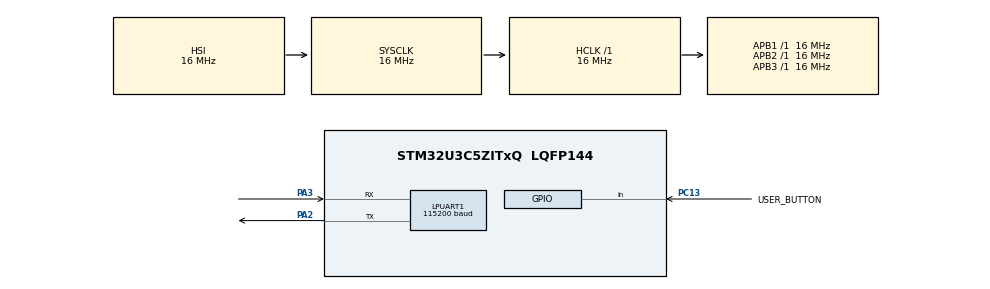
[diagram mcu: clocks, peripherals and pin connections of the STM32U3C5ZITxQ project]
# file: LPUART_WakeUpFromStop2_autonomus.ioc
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CORTEX_M33_NS.userName=CORTEX_M33
GPDMA1.DESTINC_GPDMACH0=DMA_DINC_INCREMENTED
GPDMA1.DESTINC_GPDMACH1=DMA_DINC_FIXED
GPDMA1.DIRECTION_GPDMACH0=DMA_PERIPH_TO_MEMORY
GPDMA1.DIRECTION_GPDMACH1=DMA_MEMORY_TO_PERIPH
GPDMA1.IPHANDLE_GPDMACH0-SIMPLEREQUEST_GPDMACH0=__NULL
GPDMA1.IPHANDLE_GPDMACH1-SIMPLEREQUEST_GPDMACH1=__NULL
GPDMA1.REQUEST_GPDMACH0=GPDMA1_REQUEST_LPUART1_RX
GPDMA1.REQUEST_GPDMACH1=GPDMA1_REQUEST_LPUART1_TX
GPDMA1.SRCINC_GPDMACH0=DMA_SINC_FIXED
GPDMA1.SRCINC_GPDMACH1=DMA_SINC_INCREMENTED
GPDMA1.TRANSFERALLOCATEDPORTDEST_GPDMACH0=DMA_DEST_ALLOCATED_PORT0
GPDMA1.TRANSFERALLOCATEDPORTDEST_GPDMACH1=DMA_DEST_ALLOCATED_PORT0
GPDMA1.TRANSFERALLOCATEDPORTSRC_GPDMACH0=DMA_SRC_ALLOCATED_PORT0
GPDMA1.TRANSFERALLOCATEDPORTSRC_GPDMACH1=DMA_SRC_ALLOCATED_PORT0
LPUART1.BaudRate=115200
LPUART1.ClockPrescaler=UART_PRESCALER_DIV1
LPUART1.DMADisableonRxErrorParam=UART_ADVFEATURE_DMA_ENABLEONRXERROR
LPUART1.DataInvertParam=UART_ADVFEATURE_DATAINV_DISABLE
LPUART1.FIFOMode=UART_FIFOMODE_DISABLE
LPUART1.MSBFirstParam=UART_ADVFEATURE_MSBFIRST_DISABLE
LPUART1.Mode=UART_MODE_TX_RX
LPUART1.OneBitSampling=UART_ONE_BIT_SAMPLE_DISABLE
LPUART1.OverrunDisableParam=UART_ADVFEATURE_OVERRUN_ENABLE
LPUART1.Parity=UART_PARITY_NONE
LPUART1.RXFIFOThreshold=UART_RXFIFO_THRESHOLD_1_8
LPUART1.RxPinLevelInvertParam=UART_ADVFEATURE_RXINV_DISABLE
LPUART1.StopBits=UART_STOPBITS_1
LPUART1.SwapParam=UART_ADVFEATURE_SWAP_DISABLE
LPUART1.TXFIFOThreshold=UART_TXFIFO_THRESHOLD_1_8
LPUART1.TxPinLevelInvertParam=UART_ADVFEATURE_TXINV_DISABLE
LPUART1.WordLength=UART_WORDLENGTH_8B
Mcu.Family=STM32U3
Mcu.Name=STM32U3C5ZITxQ
Mcu.Package=LQFP144
NVIC.GPDMA1_Channel0_IRQn=true\:0\:0\:false\:false\:true\:false\:true\:true
NVIC.GPDMA1_Channel1_IRQn=true\:0\:0\:false\:false\:true\:false\:true\:true
NVIC.LPUART1_IRQn=true\:0\:0\:false\:false\:true\:true\:true\:true
NVIC.PriorityGroup=NVIC_PRIORITYGROUP_4
PA2.GPIO_PuPd=GPIO_PULLUP
PA2.Mode=Asynchronous
PA2.Signal=LPUART1_TX
PA3.GPIO_PuPd=GPIO_PULLUP
PA3.Mode=Asynchronous
PA3.Signal=LPUART1_RX
PC13.GPIO_Label=USER_BUTTON
PC13.GPIO_PuPd=GPIO_PULLDOWN
PC13.Signal=GPIO_Input
ProjectManager.HeapSize=0x200
ProjectManager.StackSize=0x400
ProjectManager.TargetToolchain=EWARM V9.20
RCC.ADCFreq_Value=16000000
RCC.AHBFreq_Value=16000000
RCC.APB1Freq_Value=16000000
RCC.APB1TimFreq_Value=16000000
RCC.APB2Freq_Value=16000000
RCC.APB2TimFreq_Value=16000000
RCC.APB3Freq_Value=16000000
RCC.CortexFreq_Value=2000000
RCC.HCLKFreq_Value=16000000
RCC.HSE_VALUE=16000000
RCC.HSI48_VALUE=48000000
RCC.HSI_VALUE=16000000
RCC.LPUART1CLockSelection=RCC_LPUART1CLKSOURCE_MSIK
RCC.LSE_VALUE=32768
RCC.LSIDIV_VALUE=32000
RCC.MSIKDIV=RCC_MSI_DIV4
RCC.MSIKSource=RCC_MSI_RC1
RCC.MSISDIV=RCC_MSI_DIV1
RCC.PWR_Regulator_Voltage_Scale=PWR_REGULATOR_VOLTAGE_SCALE2
RCC.SYSCLKFreq_VALUE=16000000
RCC.SYSCLKSource=RCC_SYSCLKSOURCE_HSI
RCC.USBFreq_Value=16000000
VP_GPDMA1_VS_GPDMACH0.Mode=SIMPLEREQUEST_GPDMACH0
VP_GPDMA1_VS_GPDMACH1.Mode=SIMPLEREQUEST_GPDMACH1
VP_ICACHE_VS_ICACHE.Mode=DirectMappedCache
VP_PWR_VS_DBSignals.Mode=DisableDeadBatterySignals
VP_PWR_VS_SECSignals.Mode=Security/Privilege
board=custom

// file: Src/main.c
/* USER CODE BEGIN Header */
/**
  ******************************************************************************
  * @file    UART/LPUART_WakeUpFromStop/Src/main.c
  * @author  MCD Application Team
  * @brief   This sample code shows how to use UART through the STM32U3xx
  *          HAL API (LPUART instance) to wake up the MCU from STOP mode
  *          Two boards are used, one which enters STOP mode and the second
  *          one which sends the wake-up stimuli.
  ******************************************************************************
  * @attention
  *
  * <h2><center>&copy; Copyright (c) 2025 STMicroelectronics.
  * All rights reserved.</center></h2>
  *
  * This software component is licensed by ST under BSD 3-Clause license,
  * the "License"; You may not use this file except in compliance with the
  * License. You may obtain a copy of the License at:
  *                        opensource.org/licenses/BSD-3-Clause
  *
  ******************************************************************************
  */
/* USER CODE END Header */
#include "main.h"

/* USER CODE BEGIN Includes */
#include <string.h>
#include "stm32u3xx_nucleo.h"
/* USER CODE END Includes */

/* USER CODE BEGIN PD */
/* to enable for the board entering STOP mode,
   to disable for the board sending wake-up stimuli */
//#define BOARD_IN_STOP_MODE
/* USER CODE END PD */

UART_HandleTypeDef hlpuart1;
DMA_HandleTypeDef handle_GPDMA1_Channel1;
DMA_HandleTypeDef handle_GPDMA1_Channel0;

/* USER CODE BEGIN PV */
__IO ITStatus UartTxReady = RESET;
__IO ITStatus UartRxReady = RESET;
__IO uint32_t TransferStarted = 0U;
__IO uint32_t LedToggleDeadline = 0U;
/* Buffer used for transmission and as the reference frame for comparison. */
uint8_t aTxBuffer[] = "LPUART Stop2 autonomous";
/* Buffer used for reception */
uint8_t aRxBuffer[RXBUFFERSIZE];
/* USER CODE END PV */

void SystemClock_Config(void);
static void MX_GPIO_Init(void);
static void MX_GPDMA1_Init(void);
static void MX_ICACHE_Init(void);
static void MX_LPUART1_UART_Init(void);
/* USER CODE BEGIN PFP */
#if defined(BOARD_IN_STOP_MODE)
void SystemClock_Config_fromSTOP(void);
static HAL_StatusTypeDef PrepareReceiverAutonomousEcho(void);
static HAL_StatusTypeDef ShutdownReceiverAutonomousEcho(void);
static void EnterStop2(void);
#endif
#if !defined(BOARD_IN_STOP_MODE)
static uint16_t Buffercmp(uint8_t *pBuffer1, uint8_t *pBuffer2, uint16_t buffer_length);
#endif
/* USER CODE END PFP */

int main(void)
{

  /* MCU Configuration--------------------------------------------------------*/

  /* Reset of all peripherals, Initializes the Flash interface and the Systick. */
  HAL_Init();

  /* Configure the system clock */
  SystemClock_Config();

  /* USER CODE BEGIN SysInit */
  HAL_RCCEx_StopWakeupSysclkConfig(RCC_STOP_WKUP_SYSCLK_MSIS);
  HAL_RCCEx_EnableKernelClkInStop(RCC_KERNELCLK_MSIK);
  /* USER CODE END SysInit */

  /* Initialize all configured peripherals */
  MX_GPIO_Init();
  MX_GPDMA1_Init();
  MX_ICACHE_Init();
  MX_LPUART1_UART_Init();
  /* USER CODE BEGIN 2 */
#if defined(BOARD_IN_STOP_MODE)
  HAL_GPIO_DeInit(USER_BUTTON_GPIO_Port, USER_BUTTON_Pin);
#else
  {
    GPIO_InitTypeDef GPIO_InitStruct = {0};

    __HAL_RCC_GPIOC_CLK_ENABLE();
    GPIO_InitStruct.Pin = USER_BUTTON_Pin;
    GPIO_InitStruct.Mode = GPIO_MODE_INPUT;
    GPIO_InitStruct.Pull = GPIO_PULLDOWN;
    HAL_GPIO_Init(USER_BUTTON_GPIO_Port, &GPIO_InitStruct);
  }
#endif
  BSP_LED_Init(LD1);

#if defined(BOARD_IN_STOP_MODE)
  HAL_DBGMCU_DisableDBGStopMode();
  BSP_LED_On(LD1);
  HAL_Delay(2000);
  BSP_LED_Off(LD1);
#else
  (void)memset(aRxBuffer, 0, sizeof(aRxBuffer));
  BSP_LED_On(LD1);
  LedToggleDeadline = HAL_GetTick() + TX_LED_TOGGLE_PERIOD_MS;

  while (HAL_GPIO_ReadPin(USER_BUTTON_GPIO_Port, USER_BUTTON_Pin) == GPIO_PIN_RESET)
  {
    if ((int32_t)(HAL_GetTick() - LedToggleDeadline) >= 0)
    {
      BSP_LED_Toggle(LD1);
      LedToggleDeadline = HAL_GetTick() + TX_LED_TOGGLE_PERIOD_MS;
    }
  }

  BSP_LED_Off(LD1);

  if (HAL_UART_Receive_DMA(&hlpuart1, (uint8_t *)aRxBuffer, RXBUFFERSIZE) != HAL_OK)
  {
    Error_Handler();
  }

  if (HAL_UART_Transmit_DMA(&hlpuart1, (uint8_t *)aTxBuffer, TXBUFFERSIZE) != HAL_OK)
  {
    Error_Handler();
  }

  TransferStarted = 1U;
#endif /* BOARD_IN_STOP_MODE */
  /* USER CODE END 2 */

  /* Infinite loop */
  while (1)
  {

    /* USER CODE BEGIN 3 */
#if defined(BOARD_IN_STOP_MODE)
    if (PrepareReceiverAutonomousEcho() != HAL_OK)
    {
      Error_Handler();
    }

    EnterStop2();

    while (UartTxReady != SET)
    {
    }

    if (ShutdownReceiverAutonomousEcho() != HAL_OK)
    {
      Error_Handler();
    }

    EnterStop2();
#else
    if ((TransferStarted != 0U) && (UartRxReady == SET))
    {
      UartTxReady = RESET;
      UartRxReady = RESET;
      TransferStarted = 0U;

      if (Buffercmp((uint8_t *)aTxBuffer, (uint8_t *)aRxBuffer, RXBUFFERSIZE) != 0U)
      {
        Error_Handler();
      }

      BSP_LED_On(LD1);
      while (1)
      {
      }
    }
#endif /* BOARD_IN_STOP_MODE */
  }
  /* USER CODE END 3 */
}

void SystemClock_Config(void)
{
  RCC_OscInitTypeDef RCC_OscInitStruct = {0};
  RCC_ClkInitTypeDef RCC_ClkInitStruct = {0};

  /** Configure the System Power Supply
  */
  if (HAL_PWREx_ConfigSupply(PWR_SMPS_SUPPLY) != HAL_OK)
  {
    Error_Handler();
  }

  /** Configure the main internal regulator output voltage
  */
  if (HAL_PWREx_ControlVoltageScaling(PWR_REGULATOR_VOLTAGE_SCALE2) != HAL_OK)
  {
    Error_Handler();
  }

  /** Initializes the CPU, AHB and APB buses clocks
  */
  RCC_OscInitStruct.OscillatorType = RCC_OSCILLATORTYPE_HSI|RCC_OSCILLATORTYPE_MSIK;
  RCC_OscInitStruct.HSIState = RCC_HSI_ON;
  RCC_OscInitStruct.HSICalibrationValue = RCC_HSICALIBRATION_DEFAULT;
  RCC_OscInitStruct.MSIKState = RCC_MSI_ON;
  RCC_OscInitStruct.MSIKSource = RCC_MSI_RC1;
  RCC_OscInitStruct.MSIKDiv = RCC_MSI_DIV4;

  if (HAL_RCC_OscConfig(&RCC_OscInitStruct) != HAL_OK)
  {
    Error_Handler();
  }

  /** Initializes the CPU, AHB and APB buses clocks
  */
  RCC_ClkInitStruct.ClockType = RCC_CLOCKTYPE_HCLK|RCC_CLOCKTYPE_SYSCLK
                              |RCC_CLOCKTYPE_PCLK1|RCC_CLOCKTYPE_PCLK2
                              |RCC_CLOCKTYPE_PCLK3;
  RCC_ClkInitStruct.SYSCLKSource = RCC_SYSCLKSOURCE_HSI;
  RCC_ClkInitStruct.AHBCLKDivider = RCC_SYSCLK_DIV1;
  RCC_ClkInitStruct.APB1CLKDivider = RCC_HCLK_DIV1;
  RCC_ClkInitStruct.APB2CLKDivider = RCC_HCLK_DIV1;
  RCC_ClkInitStruct.APB3CLKDivider = RCC_HCLK_DIV1;

  if (HAL_RCC_ClockConfig(&RCC_ClkInitStruct, FLASH_LATENCY_0) != HAL_OK)
  {
    Error_Handler();
  }
}

static void MX_GPDMA1_Init(void)
{

  /* Peripheral clock enable */
  __HAL_RCC_GPDMA1_CLK_ENABLE();

  /* GPDMA1 interrupt Init */
    HAL_NVIC_SetPriority(GPDMA1_Channel0_IRQn, 0, 0);
    HAL_NVIC_EnableIRQ(GPDMA1_Channel0_IRQn);
    HAL_NVIC_SetPriority(GPDMA1_Channel1_IRQn, 0, 0);
    HAL_NVIC_EnableIRQ(GPDMA1_Channel1_IRQn);

}

static void MX_ICACHE_Init(void)
{

  /** Enable instruction cache in 1-way (direct mapped cache)
  */
  if (HAL_ICACHE_ConfigAssociativityMode(ICACHE_1WAY) != HAL_OK)
  {
    Error_Handler();
  }
  if (HAL_ICACHE_Enable() != HAL_OK)
  {
    Error_Handler();
  }

}

static void MX_LPUART1_UART_Init(void)
{

  hlpuart1.Instance = LPUART1;
  hlpuart1.Init.BaudRate = 115200;
  hlpuart1.Init.WordLength = UART_WORDLENGTH_8B;
  hlpuart1.Init.StopBits = UART_STOPBITS_1;
  hlpuart1.Init.Parity = UART_PARITY_NONE;
  hlpuart1.Init.Mode = UART_MODE_TX_RX;
  hlpuart1.Init.HwFlowCtl = UART_HWCONTROL_NONE;
  hlpuart1.Init.OneBitSampling = UART_ONE_BIT_SAMPLE_DISABLE;
  hlpuart1.Init.ClockPrescaler = UART_PRESCALER_DIV1;
  hlpuart1.AdvancedInit.AdvFeatureInit = UART_ADVFEATURE_NO_INIT;
  hlpuart1.FifoMode = UART_FIFOMODE_DISABLE;
  if (HAL_UART_Init(&hlpuart1) != HAL_OK)
  {
    Error_Handler();
  }
  if (HAL_UARTEx_SetTxFifoThreshold(&hlpuart1, UART_TXFIFO_THRESHOLD_1_8) != HAL_OK)
  {
    Error_Handler();
  }
  if (HAL_UARTEx_SetRxFifoThreshold(&hlpuart1, UART_RXFIFO_THRESHOLD_1_8) != HAL_OK)
  {
    Error_Handler();
  }
  if (HAL_UARTEx_DisableFifoMode(&hlpuart1) != HAL_OK)
  {
    Error_Handler();
  }

}

static void MX_GPIO_Init(void)
{
  GPIO_InitTypeDef GPIO_InitStruct = {0};

  /* GPIO Ports Clock Enable */
  __HAL_RCC_GPIOC_CLK_ENABLE();
  __HAL_RCC_GPIOA_CLK_ENABLE();

  /*Configure GPIO pin : USER_BUTTON_Pin */
  GPIO_InitStruct.Pin = USER_BUTTON_Pin;
  GPIO_InitStruct.Mode = GPIO_MODE_INPUT;
  GPIO_InitStruct.Pull = GPIO_PULLDOWN;
  HAL_GPIO_Init(USER_BUTTON_GPIO_Port, &GPIO_InitStruct);

}

/* USER CODE BEGIN 4 */
#if defined(BOARD_IN_STOP_MODE)
/**
  * @brief  Prepare receiver autonomous RX plus echo in Stop2.
  * @retval HAL status
  */
static HAL_StatusTypeDef PrepareReceiverAutonomousEcho(void)
{
  UART_AutonomousModeConfTypeDef autonomous_mode = {0};

  UartTxReady = RESET;
  UartRxReady = RESET;
  (void)memset(aRxBuffer, 0, sizeof(aRxBuffer));

  (void)HAL_UART_Abort(&hlpuart1);
  __HAL_UART_CLEAR_FLAG(&hlpuart1, UART_CLEAR_PEF | UART_CLEAR_FEF | UART_CLEAR_NEF |
                                    UART_CLEAR_OREF | UART_CLEAR_IDLEF | UART_CLEAR_TCF);
  __HAL_UART_SEND_REQ(&hlpuart1, UART_RXDATA_FLUSH_REQUEST);

  if (HAL_UARTEx_ClearConfigAutonomousMode(&hlpuart1) != HAL_OK)
  {
    return HAL_ERROR;
  }

  autonomous_mode.AutonomousModeState = UART_AUTONOMOUS_MODE_ENABLE;
  autonomous_mode.TriggerSelection = LPUART_GPDMA1_CH0_TCF_TRG;
  autonomous_mode.TriggerPolarity = UART_TRIG_POLARITY_RISING;
  autonomous_mode.DataSize = RXBUFFERSIZE;
  autonomous_mode.IdleFrame = UART_IDLE_FRAME_DISABLE;

  if (HAL_UARTEx_SetConfigAutonomousMode(&hlpuart1, &autonomous_mode) != HAL_OK)
  {
    return HAL_ERROR;
  }

  if (HAL_UART_Transmit_DMA(&hlpuart1, (uint8_t *)aRxBuffer, RXBUFFERSIZE) != HAL_OK)
  {
    return HAL_ERROR;
  }

  if (HAL_UART_Receive_DMA(&hlpuart1, (uint8_t *)aRxBuffer, RXBUFFERSIZE) != HAL_OK)
  {
    return HAL_ERROR;
  }

  if (HAL_UARTEx_EnableStopMode(&hlpuart1) != HAL_OK)
  {
    return HAL_ERROR;
  }

  return HAL_OK;
}

/**
  * @brief  Shut down the receiver autonomous echo path after the frame is echoed.
  * @retval HAL status
  */
static HAL_StatusTypeDef ShutdownReceiverAutonomousEcho(void)
{
  UartTxReady = RESET;
  UartRxReady = RESET;

  if (HAL_UARTEx_DisableStopMode(&hlpuart1) != HAL_OK)
  {
    return HAL_ERROR;
  }

  if (HAL_UARTEx_ClearConfigAutonomousMode(&hlpuart1) != HAL_OK)
  {
    return HAL_ERROR;
  }

  if (HAL_UART_DeInit(&hlpuart1) != HAL_OK)
  {
    return HAL_ERROR;
  }

  __HAL_RCC_GPDMA1_CLK_DISABLE();

  return HAL_OK;
}

/**
  * @brief  System Clock Configuration restored after STOP mode
  * @param  None
  * @retval None
  */
  void SystemClock_Config_fromSTOP(void)
{
  SystemClock_Config();
  HAL_RCCEx_StopWakeupSysclkConfig(RCC_STOP_WKUP_SYSCLK_MSIS);
  HAL_RCCEx_EnableKernelClkInStop(RCC_KERNELCLK_MSIK);
}

/**
  * @brief  Enter Stop2 mode and restore the system clock after wake-up.
  * @retval None
  */
  static void EnterStop2(void)
{
  HAL_SuspendTick();
  HAL_PWR_EnterSTOPMode(PWR_LOWPOWERMODE_STOP2, PWR_STOPENTRY_WFI);
  HAL_ResumeTick();
    SystemClock_Config_fromSTOP();
}
#endif

#if !defined(BOARD_IN_STOP_MODE)
/**
  * @brief  Compare two data buffers.
  * @param  pBuffer1 first buffer
  * @param  pBuffer2 second buffer
  * @param  buffer_length number of bytes to compare
  * @retval 0 when both buffers are identical, non-zero otherwise
  */
static uint16_t Buffercmp(uint8_t *pBuffer1, uint8_t *pBuffer2, uint16_t buffer_length)
{
  while (buffer_length-- != 0U)
  {
    if (*pBuffer1 != *pBuffer2)
    {
      return 1U;
    }
    pBuffer1++;
    pBuffer2++;
  }

  return 0U;
}
#endif

/**
  * @brief  UART error callbacks
  * @param  UartHandle: UART handle
  * @note   This example shows a simple way to report transfer error, and you can
  *         add your own implementation.
  * @retval None
  */
void HAL_UART_ErrorCallback(UART_HandleTypeDef *UartHandle)
{
  if (UartHandle->Instance == LPUART1)
  {
    Error_Handler();
  }
}

/**
  * @brief UART RX Complete callback
  * @param huart: uart handle
  * @retval None
  */
void HAL_UART_RxCpltCallback(UART_HandleTypeDef *huart)
{
  if (huart->Instance == LPUART1)
  {
    UartRxReady = SET;
  }
}

/**
  * @brief UART TX Complete callback
  * @param huart: uart handle
  * @retval None
  */
void HAL_UART_TxCpltCallback(UART_HandleTypeDef *huart)
{
  if (huart->Instance == LPUART1)
  {
    UartTxReady = SET;
  }
}

/* USER CODE END 4 */

void Error_Handler(void)
{
  /* USER CODE BEGIN Error_Handler_Debug */
  /* User can add his own implementation to report the HAL error return state */
  while (1)
  {
    /* In case of error, LD1 transmits a sequence of three dots, three dashes, three dots */
    BSP_LED_Off(LD1);
  }
  /* USER CODE END Error_Handler_Debug */
}
